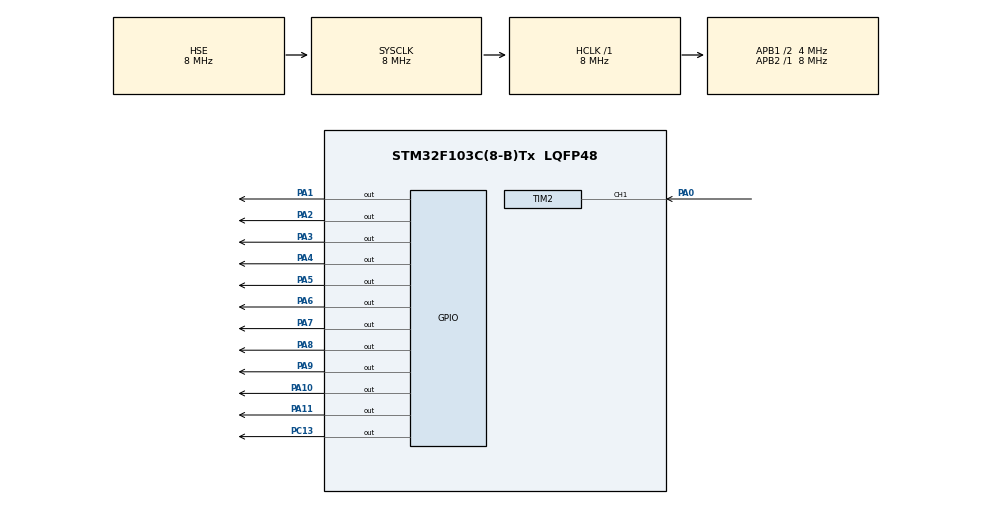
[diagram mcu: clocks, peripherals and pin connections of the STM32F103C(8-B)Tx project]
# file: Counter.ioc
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Mcu.Family=STM32F1
Mcu.Name=STM32F103C(8-B)Tx
Mcu.Package=LQFP48
NVIC.PriorityGroup=NVIC_PRIORITYGROUP_4
PA0-WKUP.GPIO_PuPd=GPIO_PULLDOWN
PA0-WKUP.Signal=S_TIM2_CH1_ETR
PA1.GPIO_ModeDefaultOutputPP=GPIO_MODE_OUTPUT_PP
PA1.GPIO_PuPd=GPIO_NOPULL
PA1.GPIO_Speed=GPIO_SPEED_FREQ_LOW
PA1.PinState=GPIO_PIN_RESET
PA1.Signal=GPIO_Output
PA10.GPIO_ModeDefaultOutputPP=GPIO_MODE_OUTPUT_PP
PA10.GPIO_PuPd=GPIO_NOPULL
PA10.GPIO_Speed=GPIO_SPEED_FREQ_LOW
PA10.PinState=GPIO_PIN_RESET
PA10.Signal=GPIO_Output
PA11.GPIO_ModeDefaultOutputPP=GPIO_MODE_OUTPUT_PP
PA11.GPIO_PuPd=GPIO_NOPULL
PA11.GPIO_Speed=GPIO_SPEED_FREQ_LOW
PA11.PinState=GPIO_PIN_RESET
PA11.Signal=GPIO_Output
PA13.Mode=Serial_Wire
PA13.Signal=SYS_JTMS-SWDIO
PA14.Mode=Serial_Wire
PA14.Signal=SYS_JTCK-SWCLK
PA2.GPIO_ModeDefaultOutputPP=GPIO_MODE_OUTPUT_PP
PA2.GPIO_PuPd=GPIO_NOPULL
PA2.GPIO_Speed=GPIO_SPEED_FREQ_LOW
PA2.PinState=GPIO_PIN_RESET
PA2.Signal=GPIO_Output
PA3.GPIO_ModeDefaultOutputPP=GPIO_MODE_OUTPUT_PP
PA3.GPIO_PuPd=GPIO_NOPULL
PA3.GPIO_Speed=GPIO_SPEED_FREQ_LOW
PA3.PinState=GPIO_PIN_RESET
PA3.Signal=GPIO_Output
PA4.GPIO_ModeDefaultOutputPP=GPIO_MODE_OUTPUT_PP
PA4.GPIO_PuPd=GPIO_NOPULL
PA4.GPIO_Speed=GPIO_SPEED_FREQ_LOW
PA4.PinState=GPIO_PIN_RESET
PA4.Signal=GPIO_Output
PA5.GPIO_ModeDefaultOutputPP=GPIO_MODE_OUTPUT_PP
PA5.GPIO_PuPd=GPIO_NOPULL
PA5.GPIO_Speed=GPIO_SPEED_FREQ_LOW
PA5.PinState=GPIO_PIN_RESET
PA5.Signal=GPIO_Output
PA6.GPIO_ModeDefaultOutputPP=GPIO_MODE_OUTPUT_PP
PA6.GPIO_PuPd=GPIO_NOPULL
PA6.GPIO_Speed=GPIO_SPEED_FREQ_LOW
PA6.PinState=GPIO_PIN_RESET
PA6.Signal=GPIO_Output
PA7.GPIO_ModeDefaultOutputPP=GPIO_MODE_OUTPUT_PP
PA7.GPIO_PuPd=GPIO_NOPULL
PA7.GPIO_Speed=GPIO_SPEED_FREQ_LOW
PA7.PinState=GPIO_PIN_RESET
PA7.Signal=GPIO_Output
PA8.GPIO_ModeDefaultOutputPP=GPIO_MODE_OUTPUT_PP
PA8.GPIO_PuPd=GPIO_NOPULL
PA8.GPIO_Speed=GPIO_SPEED_FREQ_LOW
PA8.PinState=GPIO_PIN_RESET
PA8.Signal=GPIO_Output
PA9.GPIO_ModeDefaultOutputPP=GPIO_MODE_OUTPUT_PP
PA9.GPIO_PuPd=GPIO_NOPULL
PA9.GPIO_Speed=GPIO_SPEED_FREQ_LOW
PA9.PinState=GPIO_PIN_RESET
PA9.Signal=GPIO_Output
PC13-TAMPER-RTC.GPIO_ModeDefaultOutputPP=GPIO_MODE_OUTPUT_PP
PC13-TAMPER-RTC.GPIO_PuPd=GPIO_NOPULL
PC13-TAMPER-RTC.GPIO_Speed=GPIO_SPEED_FREQ_LOW
PC13-TAMPER-RTC.PinState=GPIO_PIN_RESET
PC13-TAMPER-RTC.Signal=GPIO_Output
PD0-OSC_IN.Mode=HSE-External-Oscillator
PD0-OSC_IN.Signal=RCC_OSC_IN
PD1-OSC_OUT.Mode=HSE-External-Oscillator
PD1-OSC_OUT.Signal=RCC_OSC_OUT
ProjectManager.HeapSize=0x200
ProjectManager.StackSize=0x400
ProjectManager.TargetToolchain=MDK-ARM V5
RCC.AHBFreq_Value=8000000
RCC.APB1CLKDivider=RCC_HCLK_DIV2
RCC.APB1Freq_Value=4000000
RCC.APB1TimFreq_Value=8000000
RCC.APB2Freq_Value=8000000
RCC.APB2TimFreq_Value=8000000
RCC.EnbaleCSS=true
RCC.HCLKFreq_Value=8000000
RCC.PLLMUL=RCC_PLL_MUL9
RCC.PLLSourceVirtual=RCC_PLLSOURCE_HSE
RCC.SYSCLKFreq_VALUE=8000000
RCC.SYSCLKSource=RCC_SYSCLKSOURCE_HSE
RCC.USBFreq_Value=72000000
SH.S_TIM2_CH1_ETR.0=TIM2_CH1,TriggerSource_TI1FP1
TIM2.Period=999
TIM2.Slave_TriggerFilter=15
VP_TIM2_VS_ControllerModeClock.Mode=Clock Mode
board=custom

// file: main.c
/* USER CODE BEGIN Header */
/**
  ******************************************************************************
  * @file           : main.c
  * @brief          : Main program body
  ******************************************************************************
  * @attention
  *
  * <h2><center>&copy; Copyright (c) 2020 STMicroelectronics.
  * All rights reserved.</center></h2>
  *
  * This software component is licensed by ST under BSD 3-Clause license,
  * the "License"; You may not use this file except in compliance with the
  * License. You may obtain a copy of the License at:
  *                        opensource.org/licenses/BSD-3-Clause
  *
  ******************************************************************************
  */
/* USER CODE END Header */
#include "main.h"

/* USER CODE BEGIN Includes */
#include "lcd.h"
#include <stdio.h>
char text[16];
int counter = 0;
/* USER CODE END Includes */

TIM_HandleTypeDef htim2;

void SystemClock_Config(void);
static void MX_GPIO_Init(void);
static void MX_TIM2_Init(void);

int main(void)
{

  /* MCU Configuration--------------------------------------------------------*/

  /* Reset of all peripherals, Initializes the Flash interface and the Systick. */
  HAL_Init();

  /* Configure the system clock */
  SystemClock_Config();

  /* Initialize all configured peripherals */
  MX_GPIO_Init();
  MX_TIM2_Init();
  /* USER CODE BEGIN 2 */
	HAL_TIM_Base_Start(&htim2);
	__HAL_TIM_SetCounter(&htim2,0);
	lcd_init();
  /* USER CODE END 2 */

  /* Infinite loop */
  /* USER CODE BEGIN WHILE */
  while (1)
  {
		counter = __HAL_TIM_GetCounter(&htim2);
		sprintf(text,"counter=%3d",counter);
		lcd_gotoxy(0,0);
		lcd_puts(text);
    /* USER CODE END WHILE */

  }
}

void SystemClock_Config(void)
{
  RCC_OscInitTypeDef RCC_OscInitStruct = {0};
  RCC_ClkInitTypeDef RCC_ClkInitStruct = {0};

  /** Initializes the RCC Oscillators according to the specified parameters
  * in the RCC_OscInitTypeDef structure.
  */
  RCC_OscInitStruct.OscillatorType = RCC_OSCILLATORTYPE_HSE;
  RCC_OscInitStruct.HSEState = RCC_HSE_ON;
  RCC_OscInitStruct.PLL.PLLState = RCC_PLL_NONE;
  if (HAL_RCC_OscConfig(&RCC_OscInitStruct) != HAL_OK)
  {
    Error_Handler();
  }
  /** Initializes the CPU, AHB and APB buses clocks
  */
  RCC_ClkInitStruct.ClockType = RCC_CLOCKTYPE_HCLK|RCC_CLOCKTYPE_SYSCLK
                              |RCC_CLOCKTYPE_PCLK1|RCC_CLOCKTYPE_PCLK2;
  RCC_ClkInitStruct.SYSCLKSource = RCC_SYSCLKSOURCE_HSE;
  RCC_ClkInitStruct.AHBCLKDivider = RCC_SYSCLK_DIV1;
  RCC_ClkInitStruct.APB1CLKDivider = RCC_HCLK_DIV2;
  RCC_ClkInitStruct.APB2CLKDivider = RCC_HCLK_DIV1;

  if (HAL_RCC_ClockConfig(&RCC_ClkInitStruct, FLASH_LATENCY_0) != HAL_OK)
  {
    Error_Handler();
  }
  /** Enables the Clock Security System
  */
  HAL_RCC_EnableCSS();
}

static void MX_TIM2_Init(void)
{

  TIM_SlaveConfigTypeDef sSlaveConfig = {0};
  TIM_MasterConfigTypeDef sMasterConfig = {0};

  htim2.Instance = TIM2;
  htim2.Init.Prescaler = 0;
  htim2.Init.CounterMode = TIM_COUNTERMODE_UP;
  htim2.Init.Period = 999;
  htim2.Init.ClockDivision = TIM_CLOCKDIVISION_DIV1;
  htim2.Init.AutoReloadPreload = TIM_AUTORELOAD_PRELOAD_DISABLE;
  if (HAL_TIM_Base_Init(&htim2) != HAL_OK)
  {
    Error_Handler();
  }
  sSlaveConfig.SlaveMode = TIM_SLAVEMODE_EXTERNAL1;
  sSlaveConfig.InputTrigger = TIM_TS_TI1FP1;
  sSlaveConfig.TriggerPolarity = TIM_TRIGGERPOLARITY_RISING;
  sSlaveConfig.TriggerFilter = 15;
  if (HAL_TIM_SlaveConfigSynchro(&htim2, &sSlaveConfig) != HAL_OK)
  {
    Error_Handler();
  }
  sMasterConfig.MasterOutputTrigger = TIM_TRGO_RESET;
  sMasterConfig.MasterSlaveMode = TIM_MASTERSLAVEMODE_DISABLE;
  if (HAL_TIMEx_MasterConfigSynchronization(&htim2, &sMasterConfig) != HAL_OK)
  {
    Error_Handler();
  }

}

static void MX_GPIO_Init(void)
{
  GPIO_InitTypeDef GPIO_InitStruct = {0};

  /* GPIO Ports Clock Enable */
  __HAL_RCC_GPIOC_CLK_ENABLE();
  __HAL_RCC_GPIOD_CLK_ENABLE();
  __HAL_RCC_GPIOA_CLK_ENABLE();

  /*Configure GPIO pin Output Level */
  HAL_GPIO_WritePin(GPIOC, GPIO_PIN_13, GPIO_PIN_RESET);

  /*Configure GPIO pin Output Level */
  HAL_GPIO_WritePin(GPIOA, GPIO_PIN_1|GPIO_PIN_2|GPIO_PIN_3|GPIO_PIN_4
                          |GPIO_PIN_5|GPIO_PIN_6|GPIO_PIN_7|GPIO_PIN_8
                          |GPIO_PIN_9|GPIO_PIN_10|GPIO_PIN_11, GPIO_PIN_RESET);

  /*Configure GPIO pin : PC13 */
  GPIO_InitStruct.Pin = GPIO_PIN_13;
  GPIO_InitStruct.Mode = GPIO_MODE_OUTPUT_PP;
  GPIO_InitStruct.Pull = GPIO_NOPULL;
  GPIO_InitStruct.Speed = GPIO_SPEED_FREQ_LOW;
  HAL_GPIO_Init(GPIOC, &GPIO_InitStruct);

  /*Configure GPIO pins : PA1 PA2 PA3 PA4
                           PA5 PA6 PA7 PA8
                           PA9 PA10 PA11 */
  GPIO_InitStruct.Pin = GPIO_PIN_1|GPIO_PIN_2|GPIO_PIN_3|GPIO_PIN_4
                          |GPIO_PIN_5|GPIO_PIN_6|GPIO_PIN_7|GPIO_PIN_8
                          |GPIO_PIN_9|GPIO_PIN_10|GPIO_PIN_11;
  GPIO_InitStruct.Mode = GPIO_MODE_OUTPUT_PP;
  GPIO_InitStruct.Pull = GPIO_NOPULL;
  GPIO_InitStruct.Speed = GPIO_SPEED_FREQ_LOW;
  HAL_GPIO_Init(GPIOA, &GPIO_InitStruct);

}

void Error_Handler(void)
{
}

/************************ (C) COPYRIGHT STMicroelectronics *****END OF FILE****/
